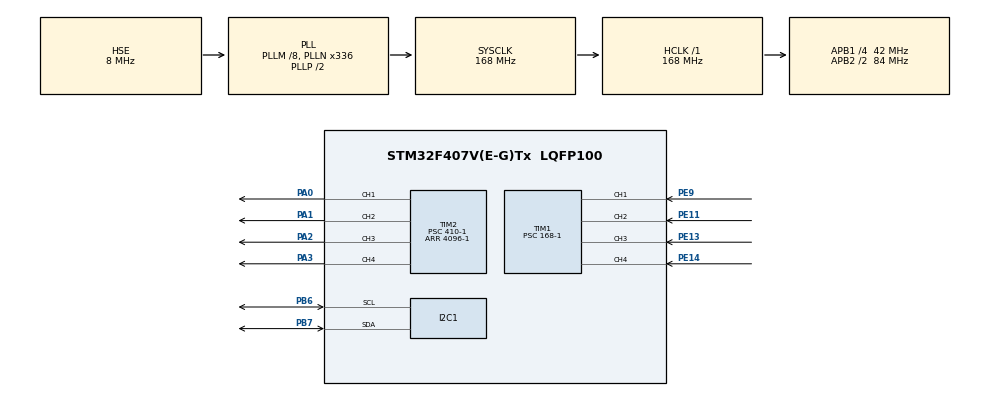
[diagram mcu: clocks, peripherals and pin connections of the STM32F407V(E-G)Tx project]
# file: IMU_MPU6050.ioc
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I2C1.DutyCycle=I2C_DUTYCYCLE_2
I2C1.I2C_Mode=I2C_Fast
Mcu.Family=STM32F4
Mcu.Name=STM32F407V(E-G)Tx
Mcu.Package=LQFP100
NVIC.PriorityGroup=NVIC_PRIORITYGROUP_0
PA0-WKUP.Signal=S_TIM2_CH1_ETR
PA1.Signal=S_TIM2_CH2
PA13.Mode=Serial_Wire
PA13.Signal=SYS_JTMS-SWDIO
PA14.Mode=Serial_Wire
PA14.Signal=SYS_JTCK-SWCLK
PA2.Signal=S_TIM2_CH3
PA3.Signal=S_TIM2_CH4
PB6.Mode=I2C
PB6.Signal=I2C1_SCL
PB7.Mode=I2C
PB7.Signal=I2C1_SDA
PE11.Signal=S_TIM1_CH2
PE13.Signal=S_TIM1_CH3
PE14.Signal=S_TIM1_CH4
PE9.Signal=S_TIM1_CH1
PH0-OSC_IN.Mode=HSE-External-Oscillator
PH0-OSC_IN.Signal=RCC_OSC_IN
PH1-OSC_OUT.Mode=HSE-External-Oscillator
PH1-OSC_OUT.Signal=RCC_OSC_OUT
ProjectManager.HeapSize=0x200
ProjectManager.StackSize=0x400
ProjectManager.TargetToolchain=STM32CubeIDE
RCC.48MHZClocksFreq_Value=48000000
RCC.AHBFreq_Value=168000000
RCC.APB1CLKDivider=RCC_HCLK_DIV4
RCC.APB1Freq_Value=42000000
RCC.APB1TimFreq_Value=84000000
RCC.APB2CLKDivider=RCC_HCLK_DIV2
RCC.APB2Freq_Value=84000000
RCC.APB2TimFreq_Value=168000000
RCC.CortexFreq_Value=168000000
RCC.HCLKFreq_Value=168000000
RCC.HSE_VALUE=8000000
RCC.HSI_VALUE=16000000
RCC.PLLM=8
RCC.PLLN=336
RCC.PLLQ=7
RCC.PLLSourceVirtual=RCC_PLLSOURCE_HSE
RCC.SYSCLKFreq_VALUE=168000000
RCC.SYSCLKSource=RCC_SYSCLKSOURCE_PLLCLK
RCC.VCOOutputFreq_Value=336000000
SH.S_TIM1_CH1.0=TIM1_CH1,Input_Capture1_from_TI1
SH.S_TIM1_CH2.0=TIM1_CH2,Input_Capture2_from_TI2
SH.S_TIM1_CH3.0=TIM1_CH3,Input_Capture3_from_TI3
SH.S_TIM1_CH4.0=TIM1_CH4,Input_Capture4_from_TI4
SH.S_TIM2_CH1_ETR.0=TIM2_CH1,PWM Generation1 CH1
SH.S_TIM2_CH2.0=TIM2_CH2,PWM Generation2 CH2
SH.S_TIM2_CH3.0=TIM2_CH3,PWM Generation3 CH3
SH.S_TIM2_CH4.0=TIM2_CH4,PWM Generation4 CH4
TIM1.AutoReloadPreload=TIM_AUTORELOAD_PRELOAD_ENABLE
TIM1.Channel-Input_Capture1_from_TI1=TIM_CHANNEL_1
TIM1.Channel-Input_Capture2_from_TI2=TIM_CHANNEL_2
TIM1.Channel-Input_Capture3_from_TI3=TIM_CHANNEL_3
TIM1.Channel-Input_Capture4_from_TI4=TIM_CHANNEL_4
TIM1.Prescaler=168-1
TIM2.AutoReloadPreload=TIM_AUTORELOAD_PRELOAD_ENABLE
TIM2.Channel-PWM\ Generation1\ CH1=TIM_CHANNEL_1
TIM2.Channel-PWM\ Generation2\ CH2=TIM_CHANNEL_2
TIM2.Channel-PWM\ Generation3\ CH3=TIM_CHANNEL_3
TIM2.Channel-PWM\ Generation4\ CH4=TIM_CHANNEL_4
TIM2.Period=4096-1
TIM2.Prescaler=410-1
VP_TIM1_VS_ClockSourceINT.Mode=Internal
VP_TIM2_VS_ClockSourceINT.Mode=Internal
board=STM32F407G-DISC1

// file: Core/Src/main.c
/* USER CODE BEGIN Header */
/**
  ******************************************************************************
  * @file           : main.c
  * @brief          : Main program body
  ******************************************************************************
  * @attention
  *
  * Copyright (c) 2023 STMicroelectronics.
  * All rights reserved.
  *
  * This software is licensed under terms that can be found in the LICENSE file
  * in the root directory of this software component.
  * If no LICENSE file comes with this software, it is provided AS-IS.
  *
  ******************************************************************************
  */
/* USER CODE END Header */
#include "main.h"
#include <stdio.h>
#include <string.h>
#include <stdlib.h>
#include <math.h>
#include <stdbool.h>
/* USER CODE BEGIN Includes */
#define MPU6050_ADDR 0x68<<1
#define PWR_MGMT_1_REG 0x6B
#define SMPLRT_DIV_REG 0x19
#define GYRO_CNFG_REG 0x1B
#define ACC_CNFG_REG 0x1C
#define LPF_REG 0x1A
/* USER CODE END Includes */

I2C_HandleTypeDef hi2c1;

TIM_HandleTypeDef htim1;
TIM_HandleTypeDef htim2;

uint8_t data;
uint8_t buffer[2],tuffer[6],cuffer[6]; // ham gyro ve acc değerlerinin tutulduğu listeler
int16_t gyro_raw[3],acc_raw[3];        // anlamlandırılmış ham değerler
float gyro_cal[3],acc_cal[3]; // kalibrasyon offsetlerini tutan liste
int16_t acc_total_vector;
float angle_pitch_gyro, angle_roll_gyro, angle_yaw_gyro;
float angle_pitch_acc, angle_roll_acc, angle_yaw_acc, angle_pitch_acc_sum, angle_roll_acc_sum, angle_yaw_acc_sum, acc_total_vector_sum;
float angle_pitch,angle_roll, angle_yaw;
int16_t raw_temp;
float temp;
int i;
float prevtime,prevtime1,time1,elapsedtime1,prevtime2,time2,elapsedtime2;
HAL_StatusTypeDef set_gyro;
void SystemClock_Config(void);
static void MX_GPIO_Init(void);
static void MX_I2C1_Init(void);
static void MX_TIM1_Init(void);
static void MX_TIM2_Init(void);

int main(void)
{

  /* MCU Configuration--------------------------------------------------------*/

  /* Reset of all peripherals, Initializes the Flash interface and the Systick. */
  HAL_Init();

  /* Configure the system clock */
  SystemClock_Config();

  /* Initialize all configured peripherals */
  MX_GPIO_Init();
  MX_I2C1_Init();
  MX_TIM1_Init();
  MX_TIM2_Init();
  data = 0x00;
  HAL_I2C_Mem_Write (&hi2c1, MPU6050_ADDR, PWR_MGMT_1_REG, 1, &data, 1, HAL_MAX_DELAY);
  //kullanılan birimin pointer olarak döndürülmesi, cihaz slave adresi, register adresi, register boyutu, verinin pointer
  //olarak döndürülmesi, verinin boyutu , zaman aşımıı değeri
  // GYRO CNFG --> +-500 derece/saniye --> 08
  data = 0x08;
  HAL_I2C_Mem_Write (&hi2c1, MPU6050_ADDR, GYRO_CNFG_REG, 1, &data, 1, HAL_MAX_DELAY);
  // ACC CNFG --> +-8g --> 10
  data = 0x10;
  HAL_I2C_Mem_Write (&hi2c1, MPU6050_ADDR, ACC_CNFG_REG, 1, &data, 1, HAL_MAX_DELAY);
  data = 0x03;
  HAL_I2C_Mem_Write (&hi2c1, MPU6050_ADDR, LPF_REG, 1, &data, 1, HAL_MAX_DELAY);

  for(i=0; i<2000; i++)
  {
	  prevtime2 = time2;
	  time2 = HAL_GetTick();
	  elapsedtime2=(time2-prevtime2)*1000;

	  cuffer[0]=0x43;
	  HAL_I2C_Master_Transmit(&hi2c1,MPU6050_ADDR,cuffer,1,HAL_MAX_DELAY);
	  HAL_I2C_Master_Receive(&hi2c1,MPU6050_ADDR,cuffer,6,HAL_MAX_DELAY);

	  gyro_raw[0] = (cuffer[0] << 8 | cuffer[1]);
	  gyro_raw[1] = (cuffer[2] << 8 | cuffer[3]);
	  gyro_raw[2] = (cuffer[4] << 8 | cuffer[5]);

	  gyro_cal[0] += gyro_raw[0];
	  gyro_cal[1] += gyro_raw[1];
	  gyro_cal[2] += gyro_raw[2];

	  HAL_Delay(3);

  }

  gyro_cal[0] /= 2000;
  gyro_cal[1] /= 2000;
  gyro_cal[2] /= 2000;

  HAL_Delay(1000);
  /* Infinite loop */
  while (1)
  {
	  	  prevtime1 = time1;
	  	  time1 = HAL_GetTick();
	  	  elapsedtime1=(time1-prevtime1)*1000;

	  	  tuffer[0]=0x3B;
	  	  HAL_I2C_Master_Transmit(&hi2c1,MPU6050_ADDR,tuffer,1,HAL_MAX_DELAY);
	  	  HAL_I2C_Master_Receive(&hi2c1,MPU6050_ADDR,tuffer,6,HAL_MAX_DELAY);

	  	  // Acc Raw Values
	  	  acc_raw[0] = (tuffer[0] << 8 | tuffer[1]);
	  	  acc_raw[1] = (tuffer[2] << 8 | tuffer[3]);
	  	  acc_raw[2] = (tuffer[4] << 8 | tuffer[5]);

	  	  buffer[0]=0x41;
	  	  HAL_I2C_Master_Transmit(&hi2c1,MPU6050_ADDR,buffer,1,HAL_MAX_DELAY);
	  	  HAL_I2C_Master_Receive(&hi2c1,MPU6050_ADDR,buffer,2,HAL_MAX_DELAY);

	  	  // Temperature Values
	  	  raw_temp = (buffer[0] << 8 | buffer[1]);
	  	  temp = (raw_temp / 340.0) + 36.53;

	  	  cuffer[0]=0x43;
	  	  HAL_I2C_Master_Transmit(&hi2c1,MPU6050_ADDR,cuffer,1,HAL_MAX_DELAY);
	  	  HAL_I2C_Master_Receive(&hi2c1,MPU6050_ADDR,cuffer,6,HAL_MAX_DELAY);

	  	  // Gyro Raw Values
	  	  gyro_raw[0] = (cuffer[0] << 8 | cuffer[1]);
	  	  gyro_raw[1] = (cuffer[2] << 8 | cuffer[3]);
	  	  gyro_raw[2] = (cuffer[4] << 8 | cuffer[5]);

	  	  gyro_raw[0] -= gyro_cal[0];
	  	  gyro_raw[1] -= gyro_cal[1];
	  	  gyro_raw[2] -= gyro_cal[2];

	  	  angle_pitch_gyro += gyro_raw[0] * 0.0000611;
	  	  angle_roll_gyro += gyro_raw[1] * 0.0000611;
	  	  angle_yaw_gyro += gyro_raw[2] * 0.0000611;

	  	  angle_pitch_gyro += angle_roll_gyro * sin(gyro_raw[2] * 0.000001066);
	  	  angle_roll_gyro -= angle_pitch_gyro * sin(gyro_raw[2] * 0.000001066);
	  	  angle_yaw_gyro -= angle_yaw_gyro * sin(gyro_raw[1] * 0.000001066);

	  	  acc_total_vector = sqrt((acc_raw[0]*acc_raw[0])+(acc_raw[1]*acc_raw[1])+(acc_raw[2]*acc_raw[2]));

	  	  //57.296 = 1 / (3.142 / 180)
	  	  angle_pitch_acc = asin((float)acc_raw[1]/acc_total_vector)* 57.296;
	  	  angle_roll_acc = asin((float)acc_raw[0]/acc_total_vector)* -57.296;
	  	  angle_yaw_acc = asin((float)acc_raw[2]/acc_total_vector)* 57.296;

	  	  angle_pitch_acc -= 1;//0.05;
	  	  angle_roll_acc -= -1.32;//-1.32;
	  	  angle_yaw_acc -= 0;
	  	  if(set_gyro){
	  		  angle_pitch = angle_pitch_gyro * 0.9996 + angle_pitch_acc * 0.0004;
	  		  angle_roll = angle_roll_gyro * 0.9996 + angle_roll_acc * 0.0004;
	  		  angle_yaw = angle_yaw_gyro * 0.9996 + angle_yaw_acc * 0.0004;
	  		}
	  	  else
	  	  {
	  		  angle_pitch = angle_pitch_acc;
	  		  set_gyro = true;
	  	  }

	  	  while((HAL_GetTick() - prevtime)*1000 < 4000);
	  	  prevtime = HAL_GetTick();

	      /* USER CODE END WHILE */

	      /* USER CODE BEGIN 3 */
  }
    /* USER CODE BEGIN 3 */
}
  /* USER CODE END 3 */

void SystemClock_Config(void)
{
  RCC_OscInitTypeDef RCC_OscInitStruct = {0};
  RCC_ClkInitTypeDef RCC_ClkInitStruct = {0};

  /** Configure the main internal regulator output voltage
  */
  __HAL_RCC_PWR_CLK_ENABLE();
  __HAL_PWR_VOLTAGESCALING_CONFIG(PWR_REGULATOR_VOLTAGE_SCALE1);

  /** Initializes the RCC Oscillators according to the specified parameters
  * in the RCC_OscInitTypeDef structure.
  */
  RCC_OscInitStruct.OscillatorType = RCC_OSCILLATORTYPE_HSE;
  RCC_OscInitStruct.HSEState = RCC_HSE_ON;
  RCC_OscInitStruct.PLL.PLLState = RCC_PLL_ON;
  RCC_OscInitStruct.PLL.PLLSource = RCC_PLLSOURCE_HSE;
  RCC_OscInitStruct.PLL.PLLM = 8;
  RCC_OscInitStruct.PLL.PLLN = 336;
  RCC_OscInitStruct.PLL.PLLP = RCC_PLLP_DIV2;
  RCC_OscInitStruct.PLL.PLLQ = 7;
  if (HAL_RCC_OscConfig(&RCC_OscInitStruct) != HAL_OK)
  {
    Error_Handler();
  }

  /** Initializes the CPU, AHB and APB buses clocks
  */
  RCC_ClkInitStruct.ClockType = RCC_CLOCKTYPE_HCLK|RCC_CLOCKTYPE_SYSCLK
                              |RCC_CLOCKTYPE_PCLK1|RCC_CLOCKTYPE_PCLK2;
  RCC_ClkInitStruct.SYSCLKSource = RCC_SYSCLKSOURCE_PLLCLK;
  RCC_ClkInitStruct.AHBCLKDivider = RCC_SYSCLK_DIV1;
  RCC_ClkInitStruct.APB1CLKDivider = RCC_HCLK_DIV4;
  RCC_ClkInitStruct.APB2CLKDivider = RCC_HCLK_DIV2;

  if (HAL_RCC_ClockConfig(&RCC_ClkInitStruct, FLASH_LATENCY_5) != HAL_OK)
  {
    Error_Handler();
  }
}

static void MX_I2C1_Init(void)
{

  hi2c1.Instance = I2C1;
  hi2c1.Init.ClockSpeed = 400000;
  hi2c1.Init.DutyCycle = I2C_DUTYCYCLE_2;
  hi2c1.Init.OwnAddress1 = 0;
  hi2c1.Init.AddressingMode = I2C_ADDRESSINGMODE_7BIT;
  hi2c1.Init.DualAddressMode = I2C_DUALADDRESS_DISABLE;
  hi2c1.Init.OwnAddress2 = 0;
  hi2c1.Init.GeneralCallMode = I2C_GENERALCALL_DISABLE;
  hi2c1.Init.NoStretchMode = I2C_NOSTRETCH_DISABLE;
  if (HAL_I2C_Init(&hi2c1) != HAL_OK)
  {
    Error_Handler();
  }

}

static void MX_TIM1_Init(void)
{

  TIM_ClockConfigTypeDef sClockSourceConfig = {0};
  TIM_MasterConfigTypeDef sMasterConfig = {0};
  TIM_IC_InitTypeDef sConfigIC = {0};

  htim1.Instance = TIM1;
  htim1.Init.Prescaler = 168-1;
  htim1.Init.CounterMode = TIM_COUNTERMODE_UP;
  htim1.Init.Period = 65535;
  htim1.Init.ClockDivision = TIM_CLOCKDIVISION_DIV1;
  htim1.Init.RepetitionCounter = 0;
  htim1.Init.AutoReloadPreload = TIM_AUTORELOAD_PRELOAD_ENABLE;
  if (HAL_TIM_Base_Init(&htim1) != HAL_OK)
  {
    Error_Handler();
  }
  sClockSourceConfig.ClockSource = TIM_CLOCKSOURCE_INTERNAL;
  if (HAL_TIM_ConfigClockSource(&htim1, &sClockSourceConfig) != HAL_OK)
  {
    Error_Handler();
  }
  if (HAL_TIM_IC_Init(&htim1) != HAL_OK)
  {
    Error_Handler();
  }
  sMasterConfig.MasterOutputTrigger = TIM_TRGO_RESET;
  sMasterConfig.MasterSlaveMode = TIM_MASTERSLAVEMODE_DISABLE;
  if (HAL_TIMEx_MasterConfigSynchronization(&htim1, &sMasterConfig) != HAL_OK)
  {
    Error_Handler();
  }
  sConfigIC.ICPolarity = TIM_INPUTCHANNELPOLARITY_RISING;
  sConfigIC.ICSelection = TIM_ICSELECTION_DIRECTTI;
  sConfigIC.ICPrescaler = TIM_ICPSC_DIV1;
  sConfigIC.ICFilter = 0;
  if (HAL_TIM_IC_ConfigChannel(&htim1, &sConfigIC, TIM_CHANNEL_1) != HAL_OK)
  {
    Error_Handler();
  }
  if (HAL_TIM_IC_ConfigChannel(&htim1, &sConfigIC, TIM_CHANNEL_2) != HAL_OK)
  {
    Error_Handler();
  }
  if (HAL_TIM_IC_ConfigChannel(&htim1, &sConfigIC, TIM_CHANNEL_3) != HAL_OK)
  {
    Error_Handler();
  }
  if (HAL_TIM_IC_ConfigChannel(&htim1, &sConfigIC, TIM_CHANNEL_4) != HAL_OK)
  {
    Error_Handler();
  }

}

static void MX_TIM2_Init(void)
{

  TIM_ClockConfigTypeDef sClockSourceConfig = {0};
  TIM_MasterConfigTypeDef sMasterConfig = {0};
  TIM_OC_InitTypeDef sConfigOC = {0};

  htim2.Instance = TIM2;
  htim2.Init.Prescaler = 410-1;
  htim2.Init.CounterMode = TIM_COUNTERMODE_UP;
  htim2.Init.Period = 4096-1;
  htim2.Init.ClockDivision = TIM_CLOCKDIVISION_DIV1;
  htim2.Init.AutoReloadPreload = TIM_AUTORELOAD_PRELOAD_ENABLE;
  if (HAL_TIM_Base_Init(&htim2) != HAL_OK)
  {
    Error_Handler();
  }
  sClockSourceConfig.ClockSource = TIM_CLOCKSOURCE_INTERNAL;
  if (HAL_TIM_ConfigClockSource(&htim2, &sClockSourceConfig) != HAL_OK)
  {
    Error_Handler();
  }
  if (HAL_TIM_PWM_Init(&htim2) != HAL_OK)
  {
    Error_Handler();
  }
  sMasterConfig.MasterOutputTrigger = TIM_TRGO_RESET;
  sMasterConfig.MasterSlaveMode = TIM_MASTERSLAVEMODE_DISABLE;
  if (HAL_TIMEx_MasterConfigSynchronization(&htim2, &sMasterConfig) != HAL_OK)
  {
    Error_Handler();
  }
  sConfigOC.OCMode = TIM_OCMODE_PWM1;
  sConfigOC.Pulse = 0;
  sConfigOC.OCPolarity = TIM_OCPOLARITY_HIGH;
  sConfigOC.OCFastMode = TIM_OCFAST_DISABLE;
  if (HAL_TIM_PWM_ConfigChannel(&htim2, &sConfigOC, TIM_CHANNEL_1) != HAL_OK)
  {
    Error_Handler();
  }
  if (HAL_TIM_PWM_ConfigChannel(&htim2, &sConfigOC, TIM_CHANNEL_2) != HAL_OK)
  {
    Error_Handler();
  }
  if (HAL_TIM_PWM_ConfigChannel(&htim2, &sConfigOC, TIM_CHANNEL_3) != HAL_OK)
  {
    Error_Handler();
  }
  if (HAL_TIM_PWM_ConfigChannel(&htim2, &sConfigOC, TIM_CHANNEL_4) != HAL_OK)
  {
    Error_Handler();
  }
  HAL_TIM_MspPostInit(&htim2);

}

static void MX_GPIO_Init(void)
{

  /* GPIO Ports Clock Enable */
  __HAL_RCC_GPIOH_CLK_ENABLE();
  __HAL_RCC_GPIOA_CLK_ENABLE();
  __HAL_RCC_GPIOE_CLK_ENABLE();
  __HAL_RCC_GPIOB_CLK_ENABLE();

}

void Error_Handler(void)
{
  __disable_irq();
  while (1)
  {
  }
}
